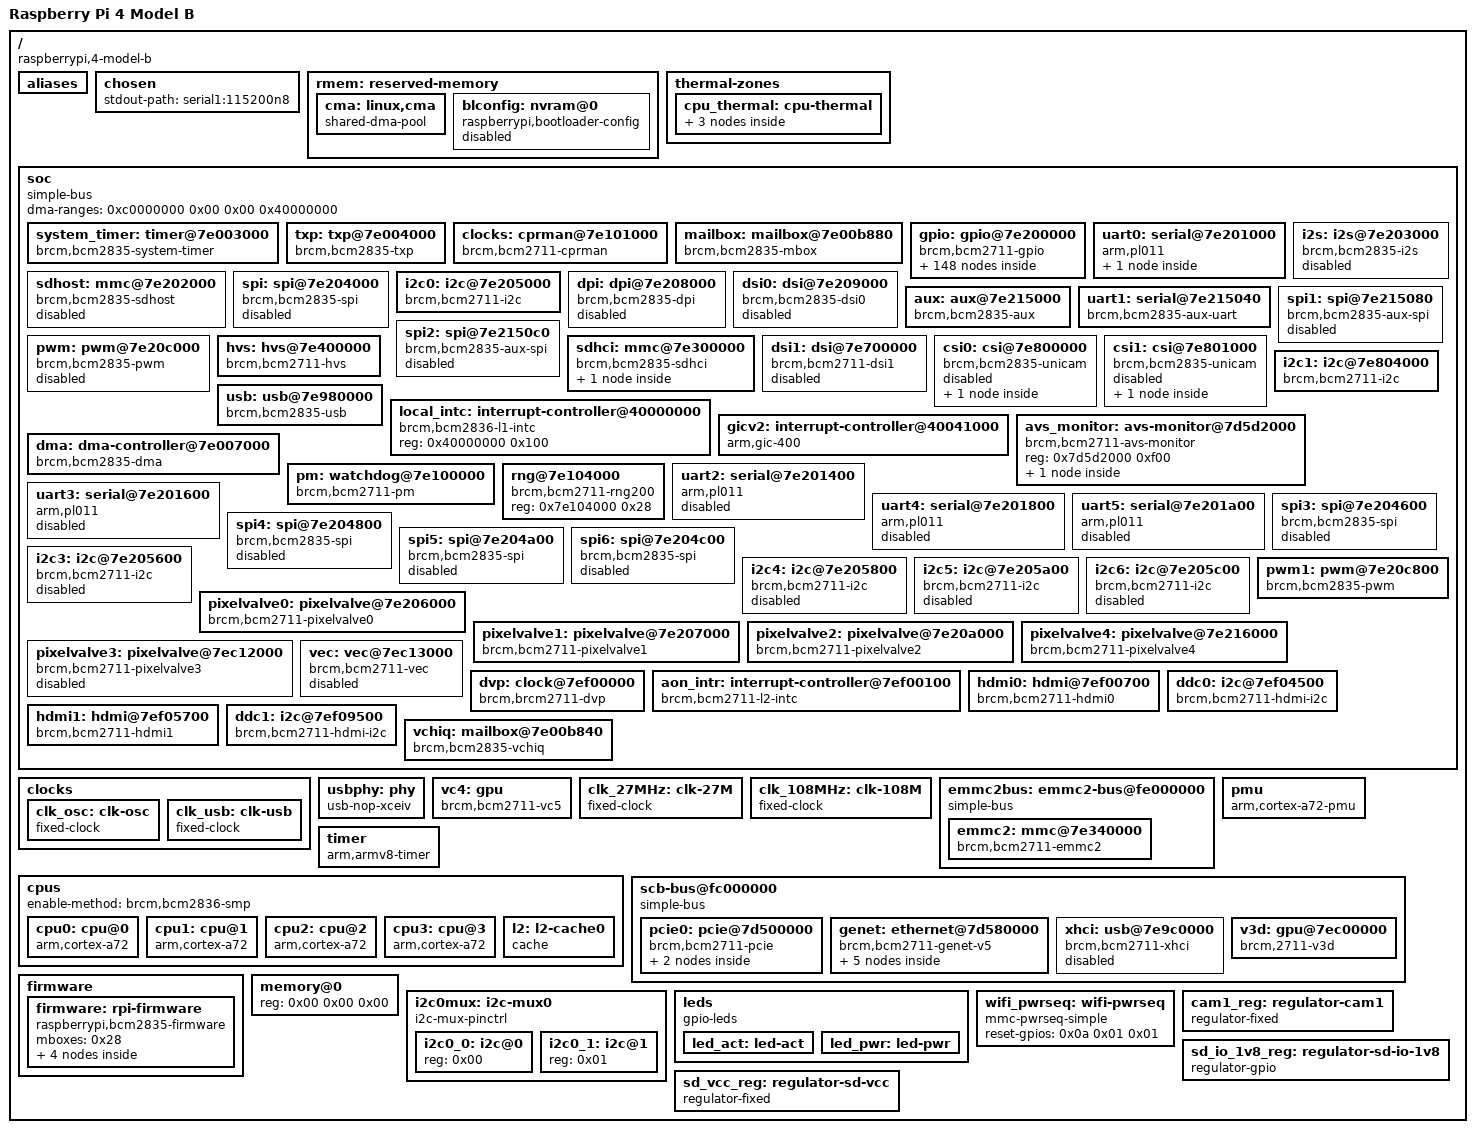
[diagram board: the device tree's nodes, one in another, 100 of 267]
/dts-v1/;

/memreserve/	0x0000000000000000 0x0000000000001000;
/ {
	compatible = "raspberrypi,4-model-b", "brcm,bcm2711";
	model = "Raspberry Pi 4 Model B";
	#address-cells = <0x02>;
	#size-cells = <0x01>;
	interrupt-parent = <0x01>;

	aliases {
		serial0 = "/soc/serial@7e201000";
		serial1 = "/soc/serial@7e215040";
		emmc2bus = "/emmc2-bus@fe000000";
		ethernet0 = "/scb-bus@fc000000/ethernet@7d580000";
		pcie0 = "/scb-bus@fc000000/pcie@7d500000";
		blconfig = "/reserved-memory/nvram@0";
	};

	chosen {
		stdout-path = "serial1:115200n8";
	};

	rmem: reserved-memory {
		#address-cells = <0x02>;
		#size-cells = <0x01>;
		ranges;
		phandle = <0x2d>;

		cma: linux,cma {
			compatible = "shared-dma-pool";
			size = <0x4000000>;
			reusable;
			linux,cma-default;
			alloc-ranges = <0x00 0x00 0x40000000>;
			phandle = <0x2e>;
		};

		blconfig: nvram@0 {
			compatible = "raspberrypi,bootloader-config", "nvmem-rmem";
			#address-cells = <0x01>;
			#size-cells = <0x01>;
			reg = <0x00 0x00 0x00>;
			no-map;
			status = "disabled";
			phandle = <0x2f>;
		};
	};

	thermal-zones {

		cpu_thermal: cpu-thermal {
			polling-delay-passive = <0x00>;
			polling-delay = <0x3e8>;
			coefficients = <0xfffffe19 0x641b8>;
			thermal-sensors = <0x02>;
			phandle = <0x30>;

			trips {

				cpu-crit {
					temperature = <0x15f90>;
					hysteresis = <0x00>;
					type = "critical";
				};
			};

			cooling-maps {
			};
		};
	};

	soc {
		compatible = "simple-bus";
		#address-cells = <0x01>;
		#size-cells = <0x01>;
		ranges = <0x7e000000 0x00 0xfe000000 0x1800000 0x7c000000 0x00 0xfc000000 0x2000000 0x40000000 0x00 0xff800000 0x800000>;
		dma-ranges = <0xc0000000 0x00 0x00 0x40000000>;

		system_timer: timer@7e003000 {
			compatible = "brcm,bcm2835-system-timer";
			reg = <0x7e003000 0x1000>;
			interrupts = <0x00 0x40 0x04 0x00 0x41 0x04 0x00 0x42 0x04 0x00 0x43 0x04>;
			clock-frequency = <0xf4240>;
			phandle = <0x31>;
		};

		txp: txp@7e004000 {
			compatible = "brcm,bcm2835-txp";
			reg = <0x7e004000 0x20>;
			interrupts = <0x00 0x4b 0x04>;
			phandle = <0x32>;
		};

		clocks: cprman@7e101000 {
			compatible = "brcm,bcm2711-cprman";
			#clock-cells = <0x01>;
			reg = <0x7e101000 0x2000>;
			clocks = <0x03 0x04 0x00 0x04 0x01 0x04 0x02 0x05 0x00 0x05 0x01 0x05 0x02>;
			phandle = <0x07>;
		};

		mailbox: mailbox@7e00b880 {
			compatible = "brcm,bcm2835-mbox";
			reg = <0x7e00b880 0x40>;
			interrupts = <0x00 0x21 0x04>;
			#mbox-cells = <0x00>;
			phandle = <0x28>;
		};

		gpio: gpio@7e200000 {
			compatible = "brcm,bcm2711-gpio";
			reg = <0x7e200000 0xb4>;
			interrupts = <0x00 0x71 0x04 0x00 0x72 0x04 0x00 0x73 0x04 0x00 0x74 0x04>;
			gpio-controller;
			#gpio-cells = <0x02>;
			interrupt-controller;
			#interrupt-cells = <0x02>;
			gpio-ranges = <0x06 0x00 0x00 0x3a>;
			gpio-line-names = "ID_SDA", "ID_SCL", "SDA1", "SCL1", "GPIO_GCLK", "GPIO5", "GPIO6", "SPI_CE1_N", "SPI_CE0_N", "SPI_MISO", "SPI_MOSI", "SPI_SCLK", "GPIO12", "GPIO13", "TXD1", "RXD1", "GPIO16", "GPIO17", "GPIO18", "GPIO19", "GPIO20", "GPIO21", "GPIO22", "GPIO23", "GPIO24", "GPIO25", "GPIO26", "GPIO27", "RGMII_MDIO", "RGMII_MDC", "CTS0", "RTS0", "TXD0", "RXD0", "SD1_CLK", "SD1_CMD", "SD1_DATA0", "SD1_DATA1", "SD1_DATA2", "SD1_DATA3", "PWM0_MISO", "PWM1_MOSI", "STATUS_LED_G_CLK", "SPIFLASH_CE_N", "SDA0", "SCL0", "RGMII_RXCLK", "RGMII_RXCTL", "RGMII_RXD0", "RGMII_RXD1", "RGMII_RXD2", "RGMII_RXD3", "RGMII_TXCLK", "RGMII_TXCTL", "RGMII_TXD0", "RGMII_TXD1", "RGMII_TXD2", "RGMII_TXD3";
			phandle = <0x06>;

			dpi_gpio0: dpi-gpio0 {
				brcm,pins = <0x00 0x01 0x02 0x03 0x04 0x05 0x06 0x07 0x08 0x09 0x0a 0x0b 0x0c 0x0d 0x0e 0x0f 0x10 0x11 0x12 0x13 0x14 0x15 0x16 0x17 0x18 0x19 0x1a 0x1b>;
				brcm,function = <0x06>;
				phandle = <0x33>;
			};

			emmc_gpio22: emmc-gpio22 {
				brcm,pins = <0x16 0x17 0x18 0x19 0x1a 0x1b>;
				brcm,function = <0x07>;
				phandle = <0x34>;
			};

			emmc_gpio34: emmc-gpio34 {
				brcm,pins = <0x22 0x23 0x24 0x25 0x26 0x27>;
				brcm,function = <0x07>;
				brcm,pull = <0x00 0x02 0x02 0x02 0x02 0x02>;
				phandle = <0x0e>;
			};

			emmc_gpio48: emmc-gpio48 {
				brcm,pins = <0x30 0x31 0x32 0x33 0x34 0x35>;
				brcm,function = <0x07>;
				phandle = <0x35>;
			};

			gpclk0_gpio4: gpclk0-gpio4 {
				brcm,pins = <0x04>;
				brcm,function = <0x04>;
				phandle = <0x36>;
			};

			gpclk1_gpio5: gpclk1-gpio5 {
				brcm,pins = <0x05>;
				brcm,function = <0x04>;
				phandle = <0x37>;
			};

			gpclk1_gpio42: gpclk1-gpio42 {
				brcm,pins = <0x2a>;
				brcm,function = <0x04>;
				phandle = <0x38>;
			};

			gpclk1_gpio44: gpclk1-gpio44 {
				brcm,pins = <0x2c>;
				brcm,function = <0x04>;
				phandle = <0x39>;
			};

			gpclk2_gpio6: gpclk2-gpio6 {
				brcm,pins = <0x06>;
				brcm,function = <0x04>;
				phandle = <0x3a>;
			};

			gpclk2_gpio43: gpclk2-gpio43 {
				brcm,pins = <0x2b>;
				brcm,function = <0x04>;
				brcm,pull = <0x00>;
				phandle = <0x3b>;
			};

			i2c0_gpio0: i2c0-gpio0 {
				brcm,pins = <0x00 0x01>;
				brcm,function = <0x04>;
				phandle = <0x2b>;
			};

			i2c0_gpio28: i2c0-gpio28 {
				brcm,pins = <0x1c 0x1d>;
				brcm,function = <0x04>;
				phandle = <0x3c>;
			};

			i2c0_gpio44: i2c0-gpio44 {
				brcm,pins = <0x2c 0x2d>;
				brcm,function = <0x05>;
				phandle = <0x2c>;
			};

			i2c1_gpio2: i2c1-gpio2 {
				brcm,pins = <0x02 0x03>;
				brcm,function = <0x04>;
				phandle = <0x11>;
			};

			i2c1_gpio44: i2c1-gpio44 {
				brcm,pins = <0x2c 0x2d>;
				brcm,function = <0x06>;
				phandle = <0x3d>;
			};

			jtag_gpio22: jtag-gpio22 {
				brcm,pins = <0x16 0x17 0x18 0x19 0x1a 0x1b>;
				brcm,function = <0x03>;
				phandle = <0x3e>;
			};

			pcm_gpio18: pcm-gpio18 {
				brcm,pins = <0x12 0x13 0x14 0x15>;
				brcm,function = <0x04>;
				phandle = <0x3f>;
			};

			pcm_gpio28: pcm-gpio28 {
				brcm,pins = <0x1c 0x1d 0x1e 0x1f>;
				brcm,function = <0x06>;
				phandle = <0x40>;
			};

			sdhost_gpio48: sdhost-gpio48 {
				brcm,pins = <0x30 0x31 0x32 0x33 0x34 0x35>;
				brcm,function = <0x04>;
				phandle = <0x41>;
			};

			spi0_gpio7: spi0-gpio7 {
				brcm,pins = <0x07 0x08 0x09 0x0a 0x0b>;
				brcm,function = <0x04>;
				phandle = <0x42>;
			};

			spi0_gpio35: spi0-gpio35 {
				brcm,pins = <0x23 0x24 0x25 0x26 0x27>;
				brcm,function = <0x04>;
				phandle = <0x43>;
			};

			spi1_gpio16: spi1-gpio16 {
				brcm,pins = <0x10 0x11 0x12 0x13 0x14 0x15>;
				brcm,function = <0x03>;
				phandle = <0x44>;
			};

			spi2_gpio40: spi2-gpio40 {
				brcm,pins = <0x28 0x29 0x2a 0x2b 0x2c 0x2d>;
				brcm,function = <0x03>;
				phandle = <0x45>;
			};

			uart0_gpio14: uart0-gpio14 {
				brcm,pins = <0x0e 0x0f>;
				brcm,function = <0x04>;
				phandle = <0x46>;
			};

			uart0_ctsrts_gpio16: uart0-ctsrts-gpio16 {
				brcm,pins = <0x10 0x11>;
				brcm,function = <0x07>;
				phandle = <0x47>;
			};

			uart0_ctsrts_gpio30: uart0-ctsrts-gpio30 {
				brcm,pins = <0x1e 0x1f>;
				brcm,function = <0x07>;
				brcm,pull = <0x02 0x00>;
				phandle = <0x08>;
			};

			uart0_gpio32: uart0-gpio32 {
				brcm,pins = <0x20 0x21>;
				brcm,function = <0x07>;
				brcm,pull = <0x00 0x02>;
				phandle = <0x09>;
			};

			uart0_gpio36: uart0-gpio36 {
				brcm,pins = <0x24 0x25>;
				brcm,function = <0x06>;
				phandle = <0x48>;
			};

			uart0_ctsrts_gpio38: uart0-ctsrts-gpio38 {
				brcm,pins = <0x26 0x27>;
				brcm,function = <0x06>;
				phandle = <0x49>;
			};

			uart1_gpio14: uart1-gpio14 {
				brcm,pins = <0x0e 0x0f>;
				brcm,function = <0x02>;
				phandle = <0x0d>;
			};

			uart1_ctsrts_gpio16: uart1-ctsrts-gpio16 {
				brcm,pins = <0x10 0x11>;
				brcm,function = <0x02>;
				phandle = <0x4a>;
			};

			uart1_gpio32: uart1-gpio32 {
				brcm,pins = <0x20 0x21>;
				brcm,function = <0x02>;
				phandle = <0x4b>;
			};

			uart1_ctsrts_gpio30: uart1-ctsrts-gpio30 {
				brcm,pins = <0x1e 0x1f>;
				brcm,function = <0x02>;
				phandle = <0x4c>;
			};

			uart1_gpio40: uart1-gpio40 {
				brcm,pins = <0x28 0x29>;
				brcm,function = <0x02>;
				phandle = <0x4d>;
			};

			uart1_ctsrts_gpio42: uart1-ctsrts-gpio42 {
				brcm,pins = <0x2a 0x2b>;
				brcm,function = <0x02>;
				phandle = <0x4e>;
			};

			gpclk0_gpio49: gpclk0-gpio49 {
				phandle = <0x4f>;

				pin-gpclk {
					pins = "gpio49";
					function = "alt1";
					bias-disable;
				};
			};

			gpclk1_gpio50: gpclk1-gpio50 {
				phandle = <0x50>;

				pin-gpclk {
					pins = "gpio50";
					function = "alt1";
					bias-disable;
				};
			};

			gpclk2_gpio51: gpclk2-gpio51 {
				phandle = <0x51>;

				pin-gpclk {
					pins = "gpio51";
					function = "alt1";
					bias-disable;
				};
			};

			i2c0_gpio46: i2c0-gpio46 {
				phandle = <0x52>;

				pin-sda {
					function = "alt0";
					pins = "gpio46";
					bias-pull-up;
				};

				pin-scl {
					function = "alt0";
					pins = "gpio47";
					bias-disable;
				};
			};

			i2c1_gpio46: i2c1-gpio46 {
				phandle = <0x53>;

				pin-sda {
					function = "alt1";
					pins = "gpio46";
					bias-pull-up;
				};

				pin-scl {
					function = "alt1";
					pins = "gpio47";
					bias-disable;
				};
			};

			i2c3_gpio2: i2c3-gpio2 {
				phandle = <0x54>;

				pin-sda {
					function = "alt5";
					pins = "gpio2";
					bias-pull-up;
				};

				pin-scl {
					function = "alt5";
					pins = "gpio3";
					bias-disable;
				};
			};

			i2c3_gpio4: i2c3-gpio4 {
				phandle = <0x55>;

				pin-sda {
					function = "alt5";
					pins = "gpio4";
					bias-pull-up;
				};

				pin-scl {
					function = "alt5";
					pins = "gpio5";
					bias-disable;
				};
			};

			i2c4_gpio6: i2c4-gpio6 {
				phandle = <0x56>;

				pin-sda {
					function = "alt5";
					pins = "gpio6";
					bias-pull-up;
				};

				pin-scl {
					function = "alt5";
					pins = "gpio7";
					bias-disable;
				};
			};

			i2c4_gpio8: i2c4-gpio8 {
				phandle = <0x57>;

				pin-sda {
					function = "alt5";
					pins = "gpio8";
					bias-pull-up;
				};

				pin-scl {
					function = "alt5";
					pins = "gpio9";
					bias-disable;
				};
			};

			i2c5_gpio10: i2c5-gpio10 {
				phandle = <0x58>;

				pin-sda {
					function = "alt5";
					pins = "gpio10";
					bias-pull-up;
				};

				pin-scl {
					function = "alt5";
					pins = "gpio11";
					bias-disable;
				};
			};

			i2c5_gpio12: i2c5-gpio12 {
				phandle = <0x59>;

				pin-sda {
					function = "alt5";
					pins = "gpio12";
					bias-pull-up;
				};

				pin-scl {
					function = "alt5";
					pins = "gpio13";
					bias-disable;
				};
			};

			i2c6_gpio0: i2c6-gpio0 {
				phandle = <0x5a>;

				pin-sda {
					function = "alt5";
					pins = "gpio0";
					bias-pull-up;
				};

				pin-scl {
					function = "alt5";
					pins = "gpio1";
					bias-disable;
				};
			};

			i2c6_gpio22: i2c6-gpio22 {
				phandle = <0x5b>;

				pin-sda {
					function = "alt5";
					pins = "gpio22";
					bias-pull-up;
				};

				pin-scl {
					function = "alt5";
					pins = "gpio23";
					bias-disable;
				};
			};

			i2c_slave_gpio8: i2c-slave-gpio8 {
				phandle = <0x5c>;

				pins-i2c-slave {
					pins = "gpio8", "gpio9", "gpio10", "gpio11";
					function = "alt3";
				};
			};

			jtag_gpio48: jtag-gpio48 {
				phandle = <0x5d>;

				pins-jtag {
					pins = "gpio48", "gpio49", "gpio50", "gpio51", "gpio52", "gpio53";
					function = "alt4";
				};
			};

			mii_gpio28: mii-gpio28 {
				phandle = <0x5e>;

				pins-mii {
					pins = "gpio28", "gpio29", "gpio30", "gpio31";
					function = "alt4";
				};
			};

			mii_gpio36: mii-gpio36 {
				phandle = <0x5f>;

				pins-mii {
					pins = "gpio36", "gpio37", "gpio38", "gpio39";
					function = "alt5";
				};
			};

			pcm_gpio50: pcm-gpio50 {
				phandle = <0x60>;

				pins-pcm {
					pins = "gpio50", "gpio51", "gpio52", "gpio53";
					function = "alt2";
				};
			};

			pwm0_0_gpio12: pwm0-0-gpio12 {
				phandle = <0x61>;

				pin-pwm {
					pins = "gpio12";
					function = "alt0";
					bias-disable;
				};
			};

			pwm0_0_gpio18: pwm0-0-gpio18 {
				phandle = <0x62>;

				pin-pwm {
					pins = "gpio18";
					function = "alt5";
					bias-disable;
				};
			};

			pwm1_0_gpio40: pwm1-0-gpio40 {
				phandle = <0x14>;

				pin-pwm {
					pins = "gpio40";
					function = "alt0";
					bias-disable;
				};
			};

			pwm0_1_gpio13: pwm0-1-gpio13 {
				phandle = <0x63>;

				pin-pwm {
					pins = "gpio13";
					function = "alt0";
					bias-disable;
				};
			};

			pwm0_1_gpio19: pwm0-1-gpio19 {
				phandle = <0x64>;

				pin-pwm {
					pins = "gpio19";
					function = "alt5";
					bias-disable;
				};
			};

			pwm1_1_gpio41: pwm1-1-gpio41 {
				phandle = <0x15>;

				pin-pwm {
					pins = "gpio41";
					function = "alt0";
					bias-disable;
				};
			};

			pwm0_1_gpio45: pwm0-1-gpio45 {
				phandle = <0x65>;

				pin-pwm {
					pins = "gpio45";
					function = "alt0";
					bias-disable;
				};
			};

			pwm0_0_gpio52: pwm0-0-gpio52 {
				phandle = <0x66>;

				pin-pwm {
					pins = "gpio52";
					function = "alt1";
					bias-disable;
				};
			};

			pwm0_1_gpio53: pwm0-1-gpio53 {
				phandle = <0x67>;

				pin-pwm {
					pins = "gpio53";
					function = "alt1";
					bias-disable;
				};
			};

			rgmii_gpio35: rgmii-gpio35 {
				phandle = <0x68>;

				pin-start-stop {
					pins = "gpio35";
					function = "alt4";
				};

				pin-rx-ok {
					pins = "gpio36";
					function = "alt4";
				};
			};

			rgmii_irq_gpio34: rgmii-irq-gpio34 {
				phandle = <0x69>;

				pin-irq {
					pins = "gpio34";
					function = "alt5";
				};
			};

			rgmii_irq_gpio39: rgmii-irq-gpio39 {
				phandle = <0x6a>;

				pin-irq {
					pins = "gpio39";
					function = "alt4";
				};
			};

			rgmii_mdio_gpio28: rgmii-mdio-gpio28 {
				phandle = <0x6b>;

				pins-mdio {
					pins = "gpio28", "gpio29";
					function = "alt5";
				};
			};

			rgmii_mdio_gpio37: rgmii-mdio-gpio37 {
				phandle = <0x6c>;

				pins-mdio {
					pins = "gpio37", "gpio38";
					function = "alt4";
				};
			};

			spi0_gpio46: spi0-gpio46 {
				phandle = <0x6d>;

				pins-spi {
					pins = "gpio46", "gpio47", "gpio48", "gpio49";
					function = "alt2";
				};
			};

			spi2_gpio46: spi2-gpio46 {
				phandle = <0x6e>;

				pins-spi {
					pins = "gpio46", "gpio47", "gpio48", "gpio49", "gpio50";
					function = "alt5";
				};
			};

			spi3_gpio0: spi3-gpio0 {
				phandle = <0x6f>;

				pins-spi {
					pins = "gpio0", "gpio1", "gpio2", "gpio3";
					function = "alt3";
				};
			};

			spi4_gpio4: spi4-gpio4 {
				phandle = <0x70>;

				pins-spi {
					pins = "gpio4", "gpio5", "gpio6", "gpio7";
					function = "alt3";
				};
			};

			spi5_gpio12: spi5-gpio12 {
				phandle = <0x71>;

				pins-spi {
					pins = "gpio12", "gpio13", "gpio14", "gpio15";
					function = "alt3";
				};
			};

			spi6_gpio18: spi6-gpio18 {
				phandle = <0x72>;

				pins-spi {
					pins = "gpio18", "gpio19", "gpio20", "gpio21";
					function = "alt3";
				};
			};

			uart2_gpio0: uart2-gpio0 {
				phandle = <0x73>;

				pin-tx {
					pins = "gpio0";
					function = "alt4";
					bias-disable;
				};

				pin-rx {
					pins = "gpio1";
					function = "alt4";
					bias-pull-up;
				};
			};

			uart2_ctsrts_gpio2: uart2-ctsrts-gpio2 {
				phandle = <0x74>;

				pin-cts {
					pins = "gpio2";
					function = "alt4";
					bias-pull-up;
				};

				pin-rts {
					pins = "gpio3";
					function = "alt4";
					bias-disable;
				};
			};

			uart3_gpio4: uart3-gpio4 {
				phandle = <0x75>;

				pin-tx {
					pins = "gpio4";
					function = "alt4";
					bias-disable;
				};

				pin-rx {
					pins = "gpio5";
					function = "alt4";
					bias-pull-up;
				};
			};

			uart3_ctsrts_gpio6: uart3-ctsrts-gpio6 {
				phandle = <0x76>;

				pin-cts {
					pins = "gpio6";
					function = "alt4";
					bias-pull-up;
				};

				pin-rts {
					pins = "gpio7";
					function = "alt4";
					bias-disable;
				};
			};

			uart4_gpio8: uart4-gpio8 {
				phandle = <0x77>;

				pin-tx {
					pins = "gpio8";
					function = "alt4";
					bias-disable;
				};

				pin-rx {
					pins = "gpio9";
					function = "alt4";
					bias-pull-up;
				};
			};

			uart4_ctsrts_gpio10: uart4-ctsrts-gpio10 {
				phandle = <0x78>;

				pin-cts {
					pins = "gpio10";
					function = "alt4";
					bias-pull-up;
				};

				pin-rts {
					pins = "gpio11";
					function = "alt4";
					bias-disable;
				};
			};

			uart5_gpio12: uart5-gpio12 {
				phandle = <0x79>;

				pin-tx {
					pins = "gpio12";
					function = "alt4";
					bias-disable;
				};

				pin-rx {
					pins = "gpio13";
					function = "alt4";
					bias-pull-up;
				};
			};

			uart5_ctsrts_gpio14: uart5-ctsrts-gpio14 {
				phandle = <0x7a>;

				pin-cts {
					pins = "gpio14";
					function = "alt4";
					bias-pull-up;
				};

				pin-rts {
					pins = "gpio15";
					function = "alt4";
					bias-disable;
				};
			};

			gpioout: gpioout {
				brcm,pins = <0x06>;
				brcm,function = <0x01>;
				phandle = <0x7b>;
			};

			alt0: alt0 {
				brcm,pins = <0x04 0x05 0x07 0x08 0x09 0x0a 0x0b>;
				brcm,function = <0x04>;
				phandle = <0x7c>;
			};
		};

		uart0: serial@7e201000 {
			compatible = "arm,pl011", "arm,primecell";
			reg = <0x7e201000 0x200>;
			interrupts = <0x00 0x79 0x04>;
			clocks = <0x07 0x13 0x07 0x14>;
			clock-names = "uartclk", "apb_pclk";
			arm,primecell-periphid = <0x341011>;
			status = "okay";
			pinctrl-names = "default";
			pinctrl-0 = <0x08 0x09>;
			uart-has-rtscts;
			phandle = <0x7d>;

			bt: bluetooth {
				compatible = "brcm,bcm43438-bt";
				max-speed = <0x1e8480>;
				shutdown-gpios = <0x0a 0x00 0x00>;
				phandle = <0x7e>;
			};
		};

		sdhost: mmc@7e202000 {
			compatible = "brcm,bcm2835-sdhost";
			reg = <0x7e202000 0x100>;
			interrupts = <0x00 0x78 0x04>;
			clocks = <0x07 0x14>;
			status = "disabled";
			phandle = <0x7f>;
		};

		i2s: i2s@7e203000 {
			compatible = "brcm,bcm2835-i2s";
			reg = <0x7e203000 0x24>;
			clocks = <0x07 0x1f>;
			status = "disabled";
			phandle = <0x80>;
		};

		spi: spi@7e204000 {
			compatible = "brcm,bcm2835-spi";
			reg = <0x7e204000 0x200>;
			interrupts = <0x00 0x76 0x04>;
			clocks = <0x07 0x14>;
			#address-cells = <0x01>;
			#size-cells = <0x00>;
			status = "disabled";
			phandle = <0x81>;
		};

		i2c0: i2c@7e205000 {
			compatible = "brcm,bcm2711-i2c", "brcm,bcm2835-i2c";
			reg = <0x7e205000 0x200>;
			interrupts = <0x00 0x75 0x04>;
			clocks = <0x07 0x14>;
			#address-cells = <0x01>;
			#size-cells = <0x00>;
			status = "okay";
			clock-frequency = <0x186a0>;
			phandle = <0x2a>;
		};

		dpi: dpi@7e208000 {
			compatible = "brcm,bcm2835-dpi";
			reg = <0x7e208000 0x8c>;
			clocks = <0x07 0x14 0x07 0x2c>;
			clock-names = "core", "pixel";
			status = "disabled";
			phandle = <0x82>;
		};

		dsi0: dsi@7e209000 {
			compatible = "brcm,bcm2835-dsi0";
			reg = <0x7e209000 0x78>;
			interrupts = <0x00 0x64 0x04>;
			#address-cells = <0x01>;
			#size-cells = <0x00>;
			#clock-cells = <0x01>;
			clocks = <0x07 0x20 0x07 0x2f 0x07 0x31>;
			clock-names = "phy", "escape", "pixel";
			clock-output-names = "dsi0_byte", "dsi0_ddr2", "dsi0_ddr";
			status = "disabled";
			power-domains = <0x0b 0x11>;
			phandle = <0x04>;
		};

		aux: aux@7e215000 {
			compatible = "brcm,bcm2835-aux";
			#clock-cells = <0x01>;
			reg = <0x7e215000 0x08>;
			clocks = <0x07 0x14>;
			phandle = <0x0c>;
		};

		uart1: serial@7e215040 {
			compatible = "brcm,bcm2835-aux-uart";
			reg = <0x7e215040 0x40>;
			interrupts = <0x00 0x5d 0x04>;
			clocks = <0x0c 0x00>;
			status = "okay";
			pinctrl-names = "default";
			pinctrl-0 = <0x0d>;
			phandle = <0x83>;
		};

		spi1: spi@7e215080 {
			compatible = "brcm,bcm2835-aux-spi";
			reg = <0x7e215080 0x40>;
			interrupts = <0x00 0x5d 0x04>;
			clocks = <0x0c 0x01>;
			#address-cells = <0x01>;
			#size-cells = <0x00>;
			status = "disabled";
			phandle = <0x84>;
		};

		spi2: spi@7e2150c0 {
			compatible = "brcm,bcm2835-aux-spi";
			reg = <0x7e2150c0 0x40>;
			interrupts = <0x00 0x5d 0x04>;
			clocks = <0x0c 0x02>;
			#address-cells = <0x01>;
			#size-cells = <0x00>;
			status = "disabled";
			phandle = <0x85>;
		};

		pwm: pwm@7e20c000 {
			compatible = "brcm,bcm2835-pwm";
			reg = <0x7e20c000 0x28>;
			clocks = <0x07 0x1e>;
			assigned-clocks = <0x07 0x1e>;
			assigned-clock-rates = <0x989680>;
			#pwm-cells = <0x03>;
			status = "disabled";
			phandle = <0x86>;
		};

		sdhci: mmc@7e300000 {
			compatible = "brcm,bcm2835-sdhci";
			reg = <0x7e300000 0x100>;
			interrupts = <0x00 0x7e 0x04>;
			clocks = <0x07 0x1c>;
			status = "okay";
			#address-cells = <0x01>;
			#size-cells = <0x00>;
			pinctrl-names = "default";
			pinctrl-0 = <0x0e>;
			bus-width = <0x04>;
			non-removable;
			mmc-pwrseq = <0x0f>;
			phandle = <0x87>;

			brcmf: wifi@1 {
				reg = <0x01>;
				compatible = "brcm,bcm4329-fmac";
				phandle = <0x88>;
			};
		};

		hvs: hvs@7e400000 {
			compatible = "brcm,bcm2711-hvs";
			reg = <0x7e400000 0x8000>;
			interrupts = <0x00 0x61 0x04>;
			clocks = <0x10 0x04>;
			phandle = <0x89>;
		};

		dsi1: dsi@7e700000 {
			compatible = "brcm,bcm2711-dsi1";
			reg = <0x7e700000 0x8c>;
			interrupts = <0x00 0x6c 0x04>;
			#address-cells = <0x01>;
			#size-cells = <0x00>;
			#clock-cells = <0x01>;
			clocks = <0x07 0x23 0x07 0x30 0x07 0x32>;
			clock-names = "phy", "escape", "pixel";
			clock-output-names = "dsi1_byte", "dsi1_ddr2", "dsi1_ddr";
			status = "disabled";
			power-domains = <0x0b 0x12>;
			phandle = <0x05>;
		};

		csi0: csi@7e800000 {
			compatible = "brcm,bcm2835-unicam";
			reg = <0x7e800000 0x800 0x7e802000 0x04>;
			reg-names = "unicam", "cmi";
			interrupts = <0x00 0x66 0x04>;
			brcm,num-data-lanes = <0x02>;
			status = "disabled";
			clocks = <0x07 0x2d 0x10 0x04>;
			clock-names = "lp", "vpu";
			power-domains = <0x0b 0x0c>;
			phandle = <0x8a>;

			port {
			};
		};

		csi1: csi@7e801000 {
			compatible = "brcm,bcm2835-unicam";
			reg = <0x7e801000 0x800 0x7e802004 0x04>;
			reg-names = "unicam", "cmi";
			interrupts = <0x00 0x67 0x04>;
			brcm,num-data-lanes = <0x04>;
			status = "disabled";
			clocks = <0x07 0x2e 0x10 0x04>;
			clock-names = "lp", "vpu";
			power-domains = <0x0b 0x0d>;
			phandle = <0x8b>;

			port {
			};
		};

		i2c1: i2c@7e804000 {
			compatible = "brcm,bcm2711-i2c", "brcm,bcm2835-i2c";
			reg = <0x7e804000 0x1000>;
			interrupts = <0x00 0x75 0x04>;
			clocks = <0x07 0x14>;
			#address-cells = <0x01>;
			#size-cells = <0x00>;
			status = "okay";
			pinctrl-names = "default";
			pinctrl-0 = <0x11>;
			clock-frequency = <0x186a0>;
			phandle = <0x8c>;
		};

		usb: usb@7e980000 {
			compatible = "brcm,bcm2835-usb";
			reg = <0x7e980000 0x10000>;
			interrupts = <0x00 0x49 0x04>;
			#address-cells = <0x01>;
			#size-cells = <0x00>;
			clocks = <0x12>;
			clock-names = "otg";
			phys = <0x13>;
			phy-names = "usb2-phy";
			power-domains = <0x0b 0x06>;
			dr_mode = "peripheral";
			g-rx-fifo-size = <0x100>;
			g-np-tx-fifo-size = <0x20>;
			g-tx-fifo-size = <0x100 0x100 0x200 0x200 0x200 0x300 0x300>;
			phandle = <0x8d>;
		};

		local_intc: interrupt-controller@40000000 {
			compatible = "brcm,bcm2836-l1-intc";
			reg = <0x40000000 0x100>;
			phandle = <0x8e>;
		};

		gicv2: interrupt-controller@40041000 {
			interrupt-controller;
			#interrupt-cells = <0x03>;
			compatible = "arm,gic-400";
			reg = <0x40041000 0x1000 0x40042000 0x2000 0x40044000 0x2000 0x40046000 0x2000>;
			interrupts = <0x01 0x09 0xf04>;
			phandle = <0x01>;
		};

		avs_monitor: avs-monitor@7d5d2000 {
			compatible = "brcm,bcm2711-avs-monitor", "syscon", "simple-mfd";
			reg = <0x7d5d2000 0xf00>;
			phandle = <0x8f>;

			thermal: thermal {
				compatible = "brcm,bcm2711-thermal";
				#thermal-sensor-cells = <0x00>;
				phandle = <0x02>;
			};
		};

		dma: dma-controller@7e007000 {
			compatible = "brcm,bcm2835-dma";
			reg = <0x7e007000 0xb00>;
			interrupts = <0x00 0x50 0x04 0x00 0x51 0x04 0x00 0x52 0x04 0x00 0x53 0x04 0x00 0x54 0x04 0x00 0x55 0x04 0x00 0x56 0x04 0x00 0x57 0x04 0x00 0x57 0x04 0x00 0x58 0x04 0x00 0x58 0x04>;
			interrupt-names = "dma0", "dma1", "dma2", "dma3", "dma4", "dma5", "dma6", "dma7", "dma8", "dma9", "dma10";
			#dma-cells = <0x01>;
			brcm,dma-channel-mask = <0x7f5>;
			phandle = <0x1a>;
		};

		pm: watchdog@7e100000 {
			compatible = "brcm,bcm2711-pm", "brcm,bcm2835-pm-wdt";
			#power-domain-cells = <0x01>;
			#reset-cells = <0x01>;
			reg = <0x7e100000 0x114 0x7e00a000 0x24 0x7ec11000 0x20>;
			reg-names = "pm", "asb", "rpivid_asb";
			clocks = <0x10 0x05 0x07 0x1d 0x07 0x17 0x07 0x16>;
			clock-names = "v3d", "peri_image", "h264", "isp";
			system-power-controller;
			phandle = <0x27>;
		};

		rng@7e104000 {
			compatible = "brcm,bcm2711-rng200";
			reg = <0x7e104000 0x28>;
		};

		uart2: serial@7e201400 {
			compatible = "arm,pl011", "arm,primecell";
			reg = <0x7e201400 0x200>;
			interrupts = <0x00 0x79 0x04>;
			clocks = <0x07 0x13 0x07 0x14>;
			clock-names = "uartclk", "apb_pclk";
			arm,primecell-periphid = <0x341011>;
			status = "disabled";
			phandle = <0x90>;
		};

		uart3: serial@7e201600 {
			compatible = "arm,pl011", "arm,primecell";
			reg = <0x7e201600 0x200>;
			interrupts = <0x00 0x79 0x04>;
			clocks = <0x07 0x13 0x07 0x14>;
			clock-names = "uartclk", "apb_pclk";
			arm,primecell-periphid = <0x341011>;
			status = "disabled";
			phandle = <0x91>;
		};

		uart4: serial@7e201800 {
			compatible = "arm,pl011", "arm,primecell";
			reg = <0x7e201800 0x200>;
			interrupts = <0x00 0x79 0x04>;
			clocks = <0x07 0x13 0x07 0x14>;
			clock-names = "uartclk", "apb_pclk";
			arm,primecell-periphid = <0x341011>;
			status = "disabled";
			phandle = <0x92>;
		};

		uart5: serial@7e201a00 {
			compatible = "arm,pl011", "arm,primecell";
			reg = <0x7e201a00 0x200>;
			interrupts = <0x00 0x79 0x04>;
			clocks = <0x07 0x13 0x07 0x14>;
			clock-names = "uartclk", "apb_pclk";
			arm,primecell-periphid = <0x341011>;
			status = "disabled";
			phandle = <0x93>;
		};

		spi3: spi@7e204600 {
			compatible = "brcm,bcm2835-spi";
			reg = <0x7e204600 0x200>;
			interrupts = <0x00 0x76 0x04>;
			clocks = <0x07 0x14>;
			#address-cells = <0x01>;
			#size-cells = <0x00>;
			status = "disabled";
			phandle = <0x94>;
		};

		spi4: spi@7e204800 {
			compatible = "brcm,bcm2835-spi";
			reg = <0x7e204800 0x200>;
			interrupts = <0x00 0x76 0x04>;
			clocks = <0x07 0x14>;
			#address-cells = <0x01>;
			#size-cells = <0x00>;
			status = "disabled";
			phandle = <0x95>;
		};

		spi5: spi@7e204a00 {
			compatible = "brcm,bcm2835-spi";
			reg = <0x7e204a00 0x200>;
			interrupts = <0x00 0x76 0x04>;
			clocks = <0x07 0x14>;
			#address-cells = <0x01>;
			#size-cells = <0x00>;
			status = "disabled";
			phandle = <0x96>;
		};

		spi6: spi@7e204c00 {
			compatible = "brcm,bcm2835-spi";
			reg = <0x7e204c00 0x200>;
			interrupts = <0x00 0x76 0x04>;
			clocks = <0x07 0x14>;
			#address-cells = <0x01>;
			#size-cells = <0x00>;
			status = "disabled";
			phandle = <0x97>;
		};

		i2c3: i2c@7e205600 {
			compatible = "brcm,bcm2711-i2c", "brcm,bcm2835-i2c";
			reg = <0x7e205600 0x200>;
			interrupts = <0x00 0x75 0x04>;
			clocks = <0x07 0x14>;
			#address-cells = <0x01>;
			#size-cells = <0x00>;
			status = "disabled";
			phandle = <0x98>;
		};

		i2c4: i2c@7e205800 {
			compatible = "brcm,bcm2711-i2c", "brcm,bcm2835-i2c";
			reg = <0x7e205800 0x200>;
			interrupts = <0x00 0x75 0x04>;
			clocks = <0x07 0x14>;
			#address-cells = <0x01>;
			#size-cells = <0x00>;
			status = "disabled";
			phandle = <0x99>;
		};

		i2c5: i2c@7e205a00 {
			compatible = "brcm,bcm2711-i2c", "brcm,bcm2835-i2c";
			reg = <0x7e205a00 0x200>;
			interrupts = <0x00 0x75 0x04>;
			clocks = <0x07 0x14>;
			#address-cells = <0x01>;
			#size-cells = <0x00>;
			status = "disabled";
			phandle = <0x9a>;
		};

		i2c6: i2c@7e205c00 {
			compatible = "brcm,bcm2711-i2c", "brcm,bcm2835-i2c";
			reg = <0x7e205c00 0x200>;
			interrupts = <0x00 0x75 0x04>;
			clocks = <0x07 0x14>;
			#address-cells = <0x01>;
			#size-cells = <0x00>;
			status = "disabled";
			phandle = <0x9b>;
		};

		pixelvalve0: pixelvalve@7e206000 {
			compatible = "brcm,bcm2711-pixelvalve0";
			reg = <0x7e206000 0x100>;
			interrupts = <0x00 0x6d 0x04>;
			status = "okay";
			phandle = <0x9c>;
		};

		pixelvalve1: pixelvalve@7e207000 {
			compatible = "brcm,bcm2711-pixelvalve1";
			reg = <0x7e207000 0x100>;
			interrupts = <0x00 0x6e 0x04>;
			status = "okay";
			phandle = <0x9d>;
		};

		pixelvalve2: pixelvalve@7e20a000 {
			compatible = "brcm,bcm2711-pixelvalve2";
			reg = <0x7e20a000 0x100>;
			interrupts = <0x00 0x65 0x04>;
			status = "okay";
			phandle = <0x9e>;
		};

		pwm1: pwm@7e20c800 {
			compatible = "brcm,bcm2835-pwm";
			reg = <0x7e20c800 0x28>;
			clocks = <0x07 0x1e>;
			assigned-clocks = <0x07 0x1e>;
			assigned-clock-rates = <0x989680>;
			#pwm-cells = <0x03>;
			status = "okay";
			pinctrl-names = "default";
			pinctrl-0 = <0x14 0x15>;
			phandle = <0x9f>;
		};

		pixelvalve4: pixelvalve@7e216000 {
			compatible = "brcm,bcm2711-pixelvalve4";
			reg = <0x7e216000 0x100>;
			interrupts = <0x00 0x6e 0x04>;
			status = "okay";
			phandle = <0xa0>;
		};

		pixelvalve3: pixelvalve@7ec12000 {
			compatible = "brcm,bcm2711-pixelvalve3";
			reg = <0x7ec12000 0x100>;
			interrupts = <0x00 0x6a 0x04>;
			status = "disabled";
			phandle = <0xa1>;
		};

		vec: vec@7ec13000 {
			compatible = "brcm,bcm2711-vec";
			reg = <0x7ec13000 0x1000>;
			clocks = <0x07 0x18>;
			interrupts = <0x00 0x7b 0x04>;
			status = "disabled";
			power-domains = <0x0b 0x07>;
			phandle = <0xa2>;
		};

		dvp: clock@7ef00000 {
			compatible = "brcm,brcm2711-dvp";
			reg = <0x7ef00000 0x10>;
			clocks = <0x16>;
			#clock-cells = <0x01>;
			#reset-cells = <0x01>;
			phandle = <0x17>;
		};

		aon_intr: interrupt-controller@7ef00100 {
			compatible = "brcm,bcm2711-l2-intc", "brcm,l2-intc";
			reg = <0x7ef00100 0x30>;
			interrupts = <0x00 0x60 0x04>;
			interrupt-controller;
			#interrupt-cells = <0x01>;
			phandle = <0x18>;
		};

		hdmi0: hdmi@7ef00700 {
			compatible = "brcm,bcm2711-hdmi0";
			reg = <0x7ef00700 0x300 0x7ef00300 0x200 0x7ef00f00 0x80 0x7ef00f80 0x80 0x7ef01b00 0x200 0x7ef01f00 0x400 0x7ef00200 0x80 0x7ef04300 0x100 0x7ef20000 0x100>;
			reg-names = "hdmi", "dvp", "phy", "rm", "packet", "metadata", "csc", "cec", "hd";
			clock-names = "hdmi", "bvb", "audio", "cec";
			resets = <0x17 0x00>;
			interrupt-parent = <0x18>;
			interrupts = <0x00 0x01 0x02 0x03 0x04 0x05>;
			interrupt-names = "cec-tx", "cec-rx", "cec-low", "wakeup", "hpd-connected", "hpd-removed";
			ddc = <0x19>;
			dmas = <0x1a 0x0a>;
			dma-names = "audio-rx";
			status = "okay";
			clocks = <0x10 0x0d 0x10 0x0e 0x17 0x00 0x1b>;
			wifi-2.4ghz-coexistence;
			phandle = <0xa3>;
		};

		ddc0: i2c@7ef04500 {
			compatible = "brcm,bcm2711-hdmi-i2c";
			reg = <0x7ef04500 0x100 0x7ef00b00 0x300>;
			reg-names = "bsc", "auto-i2c";
			clock-frequency = <0x17cdc>;
			status = "okay";
			phandle = <0x19>;
		};

		hdmi1: hdmi@7ef05700 {
			compatible = "brcm,bcm2711-hdmi1";
			reg = <0x7ef05700 0x300 0x7ef05300 0x200 0x7ef05f00 0x80 0x7ef05f80 0x80 0x7ef06b00 0x200 0x7ef06f00 0x400 0x7ef00280 0x80 0x7ef09300 0x100 0x7ef20000 0x100>;
			reg-names = "hdmi", "dvp", "phy", "rm", "packet", "metadata", "csc", "cec", "hd";
			ddc = <0x1c>;
			clock-names = "hdmi", "bvb", "audio", "cec";
			resets = <0x17 0x01>;
			interrupt-parent = <0x18>;
			interrupts = <0x08 0x07 0x06 0x09 0x0a 0x0b>;
			interrupt-names = "cec-tx", "cec-rx", "cec-low", "wakeup", "hpd-connected", "hpd-removed";
			dmas = <0x1a 0x11>;
			dma-names = "audio-rx";
			status = "okay";
			clocks = <0x10 0x0d 0x10 0x0e 0x17 0x01 0x1b>;
			wifi-2.4ghz-coexistence;
			phandle = <0xa4>;
		};

		ddc1: i2c@7ef09500 {
			compatible = "brcm,bcm2711-hdmi-i2c";
			reg = <0x7ef09500 0x100 0x7ef05b00 0x300>;
			reg-names = "bsc", "auto-i2c";
			clock-frequency = <0x17cdc>;
			status = "okay";
			phandle = <0x1c>;
		};

		vchiq: mailbox@7e00b840 {
			compatible = "brcm,bcm2835-vchiq";
			reg = <0x7e00b840 0x3c>;
			interrupts = <0x00 0x22 0x04>;
			phandle = <0xa5>;
		};
	};

	clocks {

		clk_osc: clk-osc {
			compatible = "fixed-clock";
			#clock-cells = <0x00>;
			clock-output-names = "osc";
			clock-frequency = <0x337f980>;
			phandle = <0x03>;
		};

		clk_usb: clk-usb {
			compatible = "fixed-clock";
			#clock-cells = <0x00>;
			clock-output-names = "otg";
			clock-frequency = <0x1c9c3800>;
			phandle = <0x12>;
		};
	};

	usbphy: phy {
		compatible = "usb-nop-xceiv";
		#phy-cells = <0x00>;
		phandle = <0x13>;
	};

	vc4: gpu {
		compatible = "brcm,bcm2711-vc5";
		status = "okay";
		phandle = <0xa6>;
	};

	clk_27MHz: clk-27M {
		#clock-cells = <0x00>;
		compatible = "fixed-clock";
		clock-frequency = <0x19bfcc0>;
		clock-output-names = "27MHz-clock";
		phandle = <0x1b>;
	};

	clk_108MHz: clk-108M {
		#clock-cells = <0x00>;
		compatible = "fixed-clock";
		clock-frequency = <0x66ff300>;
		clock-output-names = "108MHz-clock";
		phandle = <0x16>;
	};

	emmc2bus: emmc2-bus@fe000000 {
		compatible = "simple-bus";
		#address-cells = <0x02>;
		#size-cells = <0x01>;
		ranges = <0x00 0x7e000000 0x00 0xfe000000 0x1800000>;
		dma-ranges = <0x00 0xc0000000 0x00 0x00 0x40000000>;
		phandle = <0xa7>;

		emmc2: mmc@7e340000 {
			compatible = "brcm,bcm2711-emmc2";
			reg = <0x00 0x7e340000 0x100>;
			interrupts = <0x00 0x7e 0x04>;
			clocks = <0x07 0x33>;
			status = "okay";
			vqmmc-supply = <0x1d>;
			vmmc-supply = <0x1e>;
			broken-cd;
			phandle = <0xa8>;
		};
	};

	pmu {
		compatible = "arm,cortex-a72-pmu";
		interrupts = <0x00 0x10 0x04 0x00 0x11 0x04 0x00 0x12 0x04 0x00 0x13 0x04>;
		interrupt-affinity = <0x1f 0x20 0x21 0x22>;
	};

	timer {
		compatible = "arm,armv8-timer";
		interrupts = <0x01 0x0d 0xf08 0x01 0x0e 0xf08 0x01 0x0b 0xf08 0x01 0x0a 0xf08>;
	};

	cpus: cpus {
		#address-cells = <0x01>;
		#size-cells = <0x00>;
		enable-method = "brcm,bcm2836-smp";
		phandle = <0xa9>;

		cpu0: cpu@0 {
			device_type = "cpu";
			compatible = "arm,cortex-a72";
			reg = <0x00>;
			enable-method = "spin-table";
			cpu-release-addr = <0x00 0xd8>;
			d-cache-size = <0x8000>;
			d-cache-line-size = <0x40>;
			d-cache-sets = <0x100>;
			i-cache-size = <0xc000>;
			i-cache-line-size = <0x40>;
			i-cache-sets = <0x100>;
			next-level-cache = <0x23>;
			phandle = <0x1f>;
		};

		cpu1: cpu@1 {
			device_type = "cpu";
			compatible = "arm,cortex-a72";
			reg = <0x01>;
			enable-method = "spin-table";
			cpu-release-addr = <0x00 0xe0>;
			d-cache-size = <0x8000>;
			d-cache-line-size = <0x40>;
			d-cache-sets = <0x100>;
			i-cache-size = <0xc000>;
			i-cache-line-size = <0x40>;
			i-cache-sets = <0x100>;
			next-level-cache = <0x23>;
			phandle = <0x20>;
		};

		cpu2: cpu@2 {
			device_type = "cpu";
			compatible = "arm,cortex-a72";
			reg = <0x02>;
			enable-method = "spin-table";
			cpu-release-addr = <0x00 0xe8>;
			d-cache-size = <0x8000>;
			d-cache-line-size = <0x40>;
			d-cache-sets = <0x100>;
			i-cache-size = <0xc000>;
			i-cache-line-size = <0x40>;
			i-cache-sets = <0x100>;
			next-level-cache = <0x23>;
			phandle = <0x21>;
		};

		cpu3: cpu@3 {
			device_type = "cpu";
			compatible = "arm,cortex-a72";
			reg = <0x03>;
			enable-method = "spin-table";
			cpu-release-addr = <0x00 0xf0>;
			d-cache-size = <0x8000>;
			d-cache-line-size = <0x40>;
			d-cache-sets = <0x100>;
			i-cache-size = <0xc000>;
			i-cache-line-size = <0x40>;
			i-cache-sets = <0x100>;
			next-level-cache = <0x23>;
			phandle = <0x22>;
		};

		l2: l2-cache0 {
			compatible = "cache";
			cache-unified;
			cache-size = <0x100000>;
			cache-line-size = <0x40>;
			cache-sets = <0x400>;
			cache-level = <0x02>;
			phandle = <0x23>;
		};
	};

	scb-bus@fc000000 {
		compatible = "simple-bus";
		#address-cells = <0x02>;
		#size-cells = <0x01>;
		ranges = <0x00 0x7c000000 0x00 0xfc000000 0x3800000 0x06 0x00 0x06 0x00 0x40000000>;

		pcie0: pcie@7d500000 {
			compatible = "brcm,bcm2711-pcie";
			reg = <0x00 0x7d500000 0x9310>;
			device_type = "pci";
			#address-cells = <0x03>;
			#interrupt-cells = <0x01>;
			#size-cells = <0x02>;
			interrupts = <0x00 0x93 0x04 0x00 0x94 0x04>;
			interrupt-names = "pcie", "msi";
			interrupt-map-mask = <0x00 0x00 0x00 0x07>;
			interrupt-map = <0x00 0x00 0x00 0x01 0x01 0x00 0x8f 0x04 0x00 0x00 0x00 0x02 0x01 0x00 0x90 0x04 0x00 0x00 0x00 0x03 0x01 0x00 0x91 0x04 0x00 0x00 0x00 0x04 0x01 0x00 0x92 0x04>;
			msi-controller;
			msi-parent = <0x24>;
			ranges = <0x2000000 0x00 0xf8000000 0x06 0x00 0x00 0x4000000>;
			dma-ranges = <0x2000000 0x00 0x00 0x00 0x00 0x00 0xc0000000>;
			brcm,enable-ssc;
			phandle = <0x24>;

			pci@0,0 {
				device_type = "pci";
				#address-cells = <0x03>;
				#size-cells = <0x02>;
				ranges;
				reg = <0x00 0x00 0x00 0x00 0x00>;

				usb@0,0 {
					reg = <0x00 0x00 0x00 0x00 0x00>;
					resets = <0x25 0x00>;
				};
			};
		};

		genet: ethernet@7d580000 {
			compatible = "brcm,bcm2711-genet-v5";
			reg = <0x00 0x7d580000 0x10000>;
			#address-cells = <0x01>;
			#size-cells = <0x01>;
			interrupts = <0x00 0x9d 0x04 0x00 0x9e 0x04>;
			status = "okay";
			phy-handle = <0x26>;
			phy-mode = "rgmii-rxid";
			phandle = <0xaa>;

			genet_mdio: mdio@e14 {
				compatible = "brcm,genet-mdio-v5";
				reg = <0xe14 0x08>;
				reg-names = "mdio";
				#address-cells = <0x01>;
				#size-cells = <0x00>;
				phandle = <0xab>;

				phy1: ethernet-phy@1 {
					reg = <0x01>;
					phandle = <0x26>;

					leds {
						#address-cells = <0x01>;
						#size-cells = <0x00>;

						led@0 {
							reg = <0x00>;
							color = <0x02>;
							function = "lan";
							default-state = "keep";
						};

						led@1 {
							reg = <0x01>;
							color = <0x04>;
							function = "lan";
							default-state = "keep";
						};
					};
				};
			};
		};

		xhci: usb@7e9c0000 {
			compatible = "brcm,bcm2711-xhci", "brcm,xhci-brcm-v2";
			reg = <0x00 0x7e9c0000 0x100000>;
			#address-cells = <0x01>;
			#size-cells = <0x00>;
			interrupts = <0x00 0xb0 0x04>;
			power-domains = <0x27 0x06>;
			status = "disabled";
			phandle = <0xac>;
		};

		v3d: gpu@7ec00000 {
			compatible = "brcm,2711-v3d";
			reg = <0x00 0x7ec00000 0x4000 0x00 0x7ec04000 0x4000>;
			reg-names = "hub", "core0";
			power-domains = <0x27 0x01>;
			resets = <0x27 0x00>;
			interrupts = <0x00 0x4a 0x04>;
			clocks = <0x10 0x05>;
			phandle = <0xad>;
		};
	};

	firmware {

		firmware: rpi-firmware {
			compatible = "raspberrypi,bcm2835-firmware", "simple-mfd";
			mboxes = <0x28>;
			phandle = <0x29>;

			firmware_clocks: clocks {
				compatible = "raspberrypi,firmware-clocks";
				#clock-cells = <0x01>;
				phandle = <0x10>;
			};

			power: power {
				compatible = "raspberrypi,bcm2835-power";
				firmware = <0x29>;
				#power-domain-cells = <0x01>;
				phandle = <0x0b>;
			};

			expgpio: gpio {
				compatible = "raspberrypi,firmware-gpio";
				gpio-controller;
				#gpio-cells = <0x02>;
				status = "okay";
				gpio-line-names = "BT_ON", "WL_ON", "PWR_LED_OFF", "GLOBAL_RESET", "VDD_SD_IO_SEL", "CAM_GPIO", "SD_PWR_ON", "";
				phandle = <0x0a>;
			};

			reset: reset {
				compatible = "raspberrypi,firmware-reset";
				#reset-cells = <0x01>;
				phandle = <0x25>;
			};
		};
	};

	memory@0 {
		device_type = "memory";
		reg = <0x00 0x00 0x00>;
	};

	i2c0mux: i2c-mux0 {
		compatible = "i2c-mux-pinctrl";
		#address-cells = <0x01>;
		#size-cells = <0x00>;
		i2c-parent = <0x2a>;
		pinctrl-names = "i2c0", "i2c0-vc";
		pinctrl-0 = <0x2b>;
		pinctrl-1 = <0x2c>;
		phandle = <0xae>;

		i2c0_0: i2c@0 {
			reg = <0x00>;
			#address-cells = <0x01>;
			#size-cells = <0x00>;
			phandle = <0xaf>;
		};

		i2c0_1: i2c@1 {
			reg = <0x01>;
			#address-cells = <0x01>;
			#size-cells = <0x00>;
			phandle = <0xb0>;
		};
	};

	leds: leds {
		compatible = "gpio-leds";
		phandle = <0xb1>;

		led_act: led-act {
			label = "ACT";
			default-state = "keep";
			linux,default-trigger = "heartbeat";
			gpios = <0x06 0x2a 0x00>;
			phandle = <0xb2>;
		};

		led_pwr: led-pwr {
			label = "PWR";
			gpios = <0x0a 0x02 0x01>;
			default-state = "keep";
			linux,default-trigger = "default-on";
			phandle = <0xb3>;
		};
	};

	wifi_pwrseq: wifi-pwrseq {
		compatible = "mmc-pwrseq-simple";
		reset-gpios = <0x0a 0x01 0x01>;
		phandle = <0x0f>;
	};

	cam1_reg: regulator-cam1 {
		compatible = "regulator-fixed";
		regulator-name = "cam1-reg";
		enable-active-high;
		gpio = <0x0a 0x05 0x00>;
		phandle = <0xb4>;
	};

	sd_io_1v8_reg: regulator-sd-io-1v8 {
		compatible = "regulator-gpio";
		regulator-name = "vdd-sd-io";
		regulator-min-microvolt = <0x1b7740>;
		regulator-max-microvolt = <0x325aa0>;
		regulator-boot-on;
		regulator-always-on;
		regulator-settling-time-us = <0x1388>;
		gpios = <0x0a 0x04 0x00>;
		states = <0x1b7740 0x01 0x325aa0 0x00>;
		status = "okay";
		phandle = <0x1d>;
	};

	sd_vcc_reg: regulator-sd-vcc {
		compatible = "regulator-fixed";
		regulator-name = "vcc-sd";
		regulator-min-microvolt = <0x325aa0>;
		regulator-max-microvolt = <0x325aa0>;
		regulator-boot-on;
		enable-active-high;
		gpio = <0x0a 0x06 0x00>;
		phandle = <0x1e>;
	};

	__symbols__ {
		rmem = "/reserved-memory";
		cma = "/reserved-memory/linux,cma";
		blconfig = "/reserved-memory/nvram@0";
		cpu_thermal = "/thermal-zones/cpu-thermal";
		system_timer = "/soc/timer@7e003000";
		txp = "/soc/txp@7e004000";
		clocks = "/soc/cprman@7e101000";
		mailbox = "/soc/mailbox@7e00b880";
		gpio = "/soc/gpio@7e200000";
		dpi_gpio0 = "/soc/gpio@7e200000/dpi-gpio0";
		emmc_gpio22 = "/soc/gpio@7e200000/emmc-gpio22";
		emmc_gpio34 = "/soc/gpio@7e200000/emmc-gpio34";
		emmc_gpio48 = "/soc/gpio@7e200000/emmc-gpio48";
		gpclk0_gpio4 = "/soc/gpio@7e200000/gpclk0-gpio4";
		gpclk1_gpio5 = "/soc/gpio@7e200000/gpclk1-gpio5";
		gpclk1_gpio42 = "/soc/gpio@7e200000/gpclk1-gpio42";
		gpclk1_gpio44 = "/soc/gpio@7e200000/gpclk1-gpio44";
		gpclk2_gpio6 = "/soc/gpio@7e200000/gpclk2-gpio6";
		gpclk2_gpio43 = "/soc/gpio@7e200000/gpclk2-gpio43";
		i2c0_gpio0 = "/soc/gpio@7e200000/i2c0-gpio0";
		i2c0_gpio28 = "/soc/gpio@7e200000/i2c0-gpio28";
		i2c0_gpio44 = "/soc/gpio@7e200000/i2c0-gpio44";
		i2c1_gpio2 = "/soc/gpio@7e200000/i2c1-gpio2";
		i2c1_gpio44 = "/soc/gpio@7e200000/i2c1-gpio44";
		jtag_gpio22 = "/soc/gpio@7e200000/jtag-gpio22";
		pcm_gpio18 = "/soc/gpio@7e200000/pcm-gpio18";
		pcm_gpio28 = "/soc/gpio@7e200000/pcm-gpio28";
		sdhost_gpio48 = "/soc/gpio@7e200000/sdhost-gpio48";
		spi0_gpio7 = "/soc/gpio@7e200000/spi0-gpio7";
		spi0_gpio35 = "/soc/gpio@7e200000/spi0-gpio35";
		spi1_gpio16 = "/soc/gpio@7e200000/spi1-gpio16";
		spi2_gpio40 = "/soc/gpio@7e200000/spi2-gpio40";
		uart0_gpio14 = "/soc/gpio@7e200000/uart0-gpio14";
		uart0_ctsrts_gpio16 = "/soc/gpio@7e200000/uart0-ctsrts-gpio16";
		uart0_ctsrts_gpio30 = "/soc/gpio@7e200000/uart0-ctsrts-gpio30";
		uart0_gpio32 = "/soc/gpio@7e200000/uart0-gpio32";
		uart0_gpio36 = "/soc/gpio@7e200000/uart0-gpio36";
		uart0_ctsrts_gpio38 = "/soc/gpio@7e200000/uart0-ctsrts-gpio38";
		uart1_gpio14 = "/soc/gpio@7e200000/uart1-gpio14";
		uart1_ctsrts_gpio16 = "/soc/gpio@7e200000/uart1-ctsrts-gpio16";
		uart1_gpio32 = "/soc/gpio@7e200000/uart1-gpio32";
		uart1_ctsrts_gpio30 = "/soc/gpio@7e200000/uart1-ctsrts-gpio30";
		uart1_gpio40 = "/soc/gpio@7e200000/uart1-gpio40";
		uart1_ctsrts_gpio42 = "/soc/gpio@7e200000/uart1-ctsrts-gpio42";
		gpclk0_gpio49 = "/soc/gpio@7e200000/gpclk0-gpio49";
		gpclk1_gpio50 = "/soc/gpio@7e200000/gpclk1-gpio50";
		gpclk2_gpio51 = "/soc/gpio@7e200000/gpclk2-gpio51";
		i2c0_gpio46 = "/soc/gpio@7e200000/i2c0-gpio46";
		i2c1_gpio46 = "/soc/gpio@7e200000/i2c1-gpio46";
		i2c3_gpio2 = "/soc/gpio@7e200000/i2c3-gpio2";
		i2c3_gpio4 = "/soc/gpio@7e200000/i2c3-gpio4";
		i2c4_gpio6 = "/soc/gpio@7e200000/i2c4-gpio6";
		i2c4_gpio8 = "/soc/gpio@7e200000/i2c4-gpio8";
		i2c5_gpio10 = "/soc/gpio@7e200000/i2c5-gpio10";
		i2c5_gpio12 = "/soc/gpio@7e200000/i2c5-gpio12";
		i2c6_gpio0 = "/soc/gpio@7e200000/i2c6-gpio0";
		i2c6_gpio22 = "/soc/gpio@7e200000/i2c6-gpio22";
		i2c_slave_gpio8 = "/soc/gpio@7e200000/i2c-slave-gpio8";
		jtag_gpio48 = "/soc/gpio@7e200000/jtag-gpio48";
		mii_gpio28 = "/soc/gpio@7e200000/mii-gpio28";
		mii_gpio36 = "/soc/gpio@7e200000/mii-gpio36";
		pcm_gpio50 = "/soc/gpio@7e200000/pcm-gpio50";
		pwm0_0_gpio12 = "/soc/gpio@7e200000/pwm0-0-gpio12";
		pwm0_0_gpio18 = "/soc/gpio@7e200000/pwm0-0-gpio18";
		pwm1_0_gpio40 = "/soc/gpio@7e200000/pwm1-0-gpio40";
		pwm0_1_gpio13 = "/soc/gpio@7e200000/pwm0-1-gpio13";
		pwm0_1_gpio19 = "/soc/gpio@7e200000/pwm0-1-gpio19";
		pwm1_1_gpio41 = "/soc/gpio@7e200000/pwm1-1-gpio41";
		pwm0_1_gpio45 = "/soc/gpio@7e200000/pwm0-1-gpio45";
		pwm0_0_gpio52 = "/soc/gpio@7e200000/pwm0-0-gpio52";
		pwm0_1_gpio53 = "/soc/gpio@7e200000/pwm0-1-gpio53";
		rgmii_gpio35 = "/soc/gpio@7e200000/rgmii-gpio35";
		rgmii_irq_gpio34 = "/soc/gpio@7e200000/rgmii-irq-gpio34";
		rgmii_irq_gpio39 = "/soc/gpio@7e200000/rgmii-irq-gpio39";
		rgmii_mdio_gpio28 = "/soc/gpio@7e200000/rgmii-mdio-gpio28";
		rgmii_mdio_gpio37 = "/soc/gpio@7e200000/rgmii-mdio-gpio37";
		spi0_gpio46 = "/soc/gpio@7e200000/spi0-gpio46";
		spi2_gpio46 = "/soc/gpio@7e200000/spi2-gpio46";
		spi3_gpio0 = "/soc/gpio@7e200000/spi3-gpio0";
		spi4_gpio4 = "/soc/gpio@7e200000/spi4-gpio4";
		spi5_gpio12 = "/soc/gpio@7e200000/spi5-gpio12";
		spi6_gpio18 = "/soc/gpio@7e200000/spi6-gpio18";
		uart2_gpio0 = "/soc/gpio@7e200000/uart2-gpio0";
		uart2_ctsrts_gpio2 = "/soc/gpio@7e200000/uart2-ctsrts-gpio2";
		uart3_gpio4 = "/soc/gpio@7e200000/uart3-gpio4";
		uart3_ctsrts_gpio6 = "/soc/gpio@7e200000/uart3-ctsrts-gpio6";
		uart4_gpio8 = "/soc/gpio@7e200000/uart4-gpio8";
		uart4_ctsrts_gpio10 = "/soc/gpio@7e200000/uart4-ctsrts-gpio10";
		uart5_gpio12 = "/soc/gpio@7e200000/uart5-gpio12";
		uart5_ctsrts_gpio14 = "/soc/gpio@7e200000/uart5-ctsrts-gpio14";
		gpioout = "/soc/gpio@7e200000/gpioout";
		alt0 = "/soc/gpio@7e200000/alt0";
		uart0 = "/soc/serial@7e201000";
		bt = "/soc/serial@7e201000/bluetooth";
		sdhost = "/soc/mmc@7e202000";
		i2s = "/soc/i2s@7e203000";
		spi = "/soc/spi@7e204000";
		i2c0 = "/soc/i2c@7e205000";
		dpi = "/soc/dpi@7e208000";
		dsi0 = "/soc/dsi@7e209000";
		aux = "/soc/aux@7e215000";
		uart1 = "/soc/serial@7e215040";
		spi1 = "/soc/spi@7e215080";
		spi2 = "/soc/spi@7e2150c0";
		pwm = "/soc/pwm@7e20c000";
		sdhci = "/soc/mmc@7e300000";
		brcmf = "/soc/mmc@7e300000/wifi@1";
		hvs = "/soc/hvs@7e400000";
		dsi1 = "/soc/dsi@7e700000";
		csi0 = "/soc/csi@7e800000";
		csi1 = "/soc/csi@7e801000";
		i2c1 = "/soc/i2c@7e804000";
		usb = "/soc/usb@7e980000";
		local_intc = "/soc/interrupt-controller@40000000";
		gicv2 = "/soc/interrupt-controller@40041000";
		avs_monitor = "/soc/avs-monitor@7d5d2000";
		thermal = "/soc/avs-monitor@7d5d2000/thermal";
		dma = "/soc/dma-controller@7e007000";
		pm = "/soc/watchdog@7e100000";
		uart2 = "/soc/serial@7e201400";
		uart3 = "/soc/serial@7e201600";
		uart4 = "/soc/serial@7e201800";
		uart5 = "/soc/serial@7e201a00";
		spi3 = "/soc/spi@7e204600";
		spi4 = "/soc/spi@7e204800";
		spi5 = "/soc/spi@7e204a00";
		spi6 = "/soc/spi@7e204c00";
		i2c3 = "/soc/i2c@7e205600";
		i2c4 = "/soc/i2c@7e205800";
		i2c5 = "/soc/i2c@7e205a00";
		i2c6 = "/soc/i2c@7e205c00";
		pixelvalve0 = "/soc/pixelvalve@7e206000";
		pixelvalve1 = "/soc/pixelvalve@7e207000";
		pixelvalve2 = "/soc/pixelvalve@7e20a000";
		pwm1 = "/soc/pwm@7e20c800";
		pixelvalve4 = "/soc/pixelvalve@7e216000";
		pixelvalve3 = "/soc/pixelvalve@7ec12000";
		vec = "/soc/vec@7ec13000";
		dvp = "/soc/clock@7ef00000";
		aon_intr = "/soc/interrupt-controller@7ef00100";
		hdmi0 = "/soc/hdmi@7ef00700";
		ddc0 = "/soc/i2c@7ef04500";
		hdmi1 = "/soc/hdmi@7ef05700";
		ddc1 = "/soc/i2c@7ef09500";
		vchiq = "/soc/mailbox@7e00b840";
		clk_osc = "/clocks/clk-osc";
		clk_usb = "/clocks/clk-usb";
		usbphy = "/phy";
		vc4 = "/gpu";
		clk_27MHz = "/clk-27M";
		clk_108MHz = "/clk-108M";
		emmc2bus = "/emmc2-bus@fe000000";
		emmc2 = "/emmc2-bus@fe000000/mmc@7e340000";
		cpus = "/cpus";
		cpu0 = "/cpus/cpu@0";
		cpu1 = "/cpus/cpu@1";
		cpu2 = "/cpus/cpu@2";
		cpu3 = "/cpus/cpu@3";
		l2 = "/cpus/l2-cache0";
		pcie0 = "/scb-bus@fc000000/pcie@7d500000";
		genet = "/scb-bus@fc000000/ethernet@7d580000";
		genet_mdio = "/scb-bus@fc000000/ethernet@7d580000/mdio@e14";
		phy1 = "/scb-bus@fc000000/ethernet@7d580000/mdio@e14/ethernet-phy@1";
		xhci = "/scb-bus@fc000000/usb@7e9c0000";
		v3d = "/scb-bus@fc000000/gpu@7ec00000";
		firmware = "/firmware/rpi-firmware";
		firmware_clocks = "/firmware/rpi-firmware/clocks";
		power = "/firmware/rpi-firmware/power";
		expgpio = "/firmware/rpi-firmware/gpio";
		reset = "/firmware/rpi-firmware/reset";
		i2c0mux = "/i2c-mux0";
		i2c0_0 = "/i2c-mux0/i2c@0";
		i2c0_1 = "/i2c-mux0/i2c@1";
		leds = "/leds";
		led_act = "/leds/led-act";
		led_pwr = "/leds/led-pwr";
		wifi_pwrseq = "/wifi-pwrseq";
		cam1_reg = "/regulator-cam1";
		sd_io_1v8_reg = "/regulator-sd-io-1v8";
		sd_vcc_reg = "/regulator-sd-vcc";
	};
};
